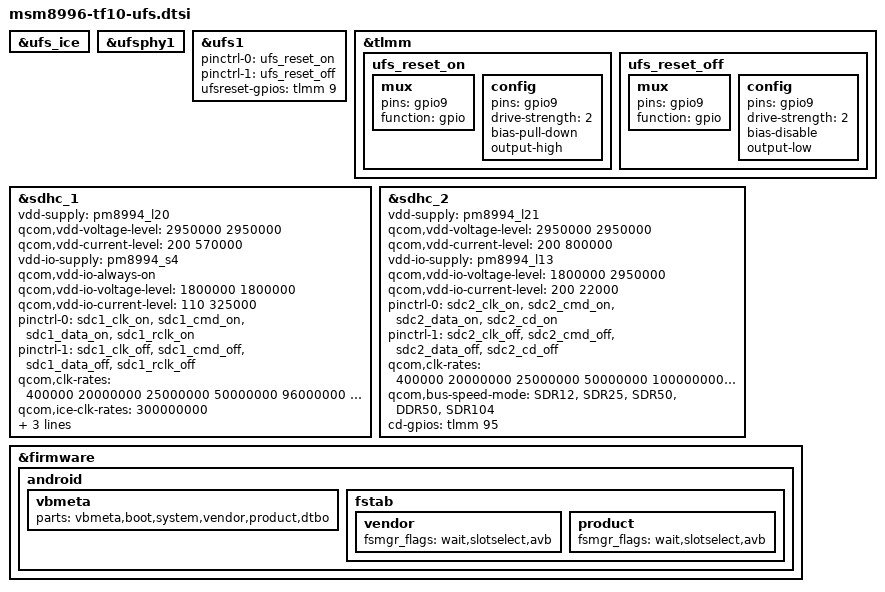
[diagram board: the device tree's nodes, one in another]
/* Copyright (c) 2015, The Linux Foundation. All rights reserved.
 *
 * This program is free software; you can redistribute it and/or modify
 * it under the terms of the GNU General Public License version 2 and
 * only version 2 as published by the Free Software Foundation.
 *
 * This program is distributed in the hope that it will be useful,
 * but WITHOUT ANY WARRANTY; without even the implied warranty of
 * MERCHANTABILITY or FITNESS FOR A PARTICULAR PURPOSE.  See the
 * GNU General Public License for more details.
 */

&ufs_ice {
        status = "ok";
};

&ufsphy1 {
        status = "ok";
};

&ufs1 {
        status = "ok";
};

&tlmm {
	ufs_reset_on: ufs_reset_on {
		mux {
			  pins = "gpio9";
			  function = "gpio";
		};

		config {
			  pins = "gpio9";
			  drive-strength = <2>;
			  bias-pull-down;
			  output-high;
		};
	};

	ufs_reset_off: ufs_reset_off {
		mux {
			pins = "gpio9";
			function = "gpio";
		};

		config {
		   pins = "gpio9";
		   drive-strength = <2>;
		   bias-disable;
		   output-low;
		};
	};
};

&ufs1 {
        pinctrl-names = "ufs_res_in_on", "ufs_res_in_off";
        pinctrl-0 = <&ufs_reset_on>;
        pinctrl-1 = <&ufs_reset_off>;
        /* H+ hw - invert signal by FET - UFS_RESET_N is low active */
        ufsreset-gpios = <&tlmm 9 0x0>;
};

&sdhc_1 {
	vdd-supply = <&pm8994_l20>;
	qcom,vdd-voltage-level = <2950000 2950000>;
	qcom,vdd-current-level = <200 570000>;

	vdd-io-supply = <&pm8994_s4>;
	qcom,vdd-io-always-on;
	qcom,vdd-io-voltage-level = <1800000 1800000>;
	qcom,vdd-io-current-level = <110 325000>;

	pinctrl-names = "active", "sleep";
	pinctrl-0 = <&sdc1_clk_on &sdc1_cmd_on &sdc1_data_on &sdc1_rclk_on>;
	pinctrl-1 = <&sdc1_clk_off &sdc1_cmd_off &sdc1_data_off &sdc1_rclk_off>;

	qcom,clk-rates = <400000 20000000 25000000 50000000 96000000 192000000 384000000>;
	qcom,ice-clk-rates = <300000000>;
	qcom,nonremovable;
	qcom,bus-speed-mode = "HS400_1p8v", "HS200_1p8v", "DDR_1p8v";

	status = "ok";
};

&sdhc_2 {
	vdd-supply = <&pm8994_l21>;
	qcom,vdd-voltage-level = <2950000 2950000>;
	qcom,vdd-current-level = <200 800000>;

	vdd-io-supply = <&pm8994_l13>;
	qcom,vdd-io-voltage-level = <1800000 2950000>;
	qcom,vdd-io-current-level = <200 22000>;

	pinctrl-names = "active", "sleep";
	pinctrl-0 = <&sdc2_clk_on  &sdc2_cmd_on &sdc2_data_on &sdc2_cd_on>;
	pinctrl-1 = <&sdc2_clk_off &sdc2_cmd_off &sdc2_data_off &sdc2_cd_off>;

	qcom,clk-rates = <400000 20000000 25000000 50000000 100000000 200000000>;
	qcom,bus-speed-mode = "SDR12", "SDR25", "SDR50", "DDR50", "SDR104";

	/* Though Active-Low-H/W-logic is actually adopted in circuit-diagram,
	Logic-value is reversed in 3in2-socket not in 2in1-socket.
	1: Active-Low, 0: Active-High
	*/
	cd-gpios = <&tlmm 95 0x0>;

	status = "ok";
};

&firmware {
	android {
		vbmeta {
			parts = "vbmeta,boot,system,vendor,product,dtbo";
		};

		fstab {
			vendor {
				fsmgr_flags = "wait,slotselect,avb";
			};
			product {
				fsmgr_flags = "wait,slotselect,avb";
			};
		};
	};
};
